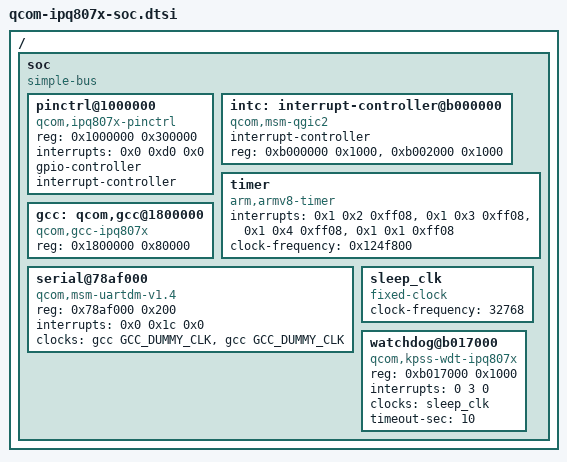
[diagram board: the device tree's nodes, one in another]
/*
 * Copyright (c) 2016, The Linux Foundation. All rights reserved.
 *
 * Permission to use, copy, modify, and/or distribute this software for any
 * purpose with or without fee is hereby granted, provided that the above
 * copyright notice and this permission notice appear in all copies.
 *
 * THE SOFTWARE IS PROVIDED "AS IS" AND THE AUTHOR DISCLAIMS ALL WARRANTIES
 * WITH REGARD TO THIS SOFTWARE INCLUDING ALL IMPLIED WARRANTIES OF
 * MERCHANTABILITY AND FITNESS. IN NO EVENT SHALL THE AUTHOR BE LIABLE FOR
 * ANY SPECIAL, DIRECT, INDIRECT, OR CONSEQUENTIAL DAMAGES OR ANY DAMAGES
 * WHATSOEVER RESULTING FROM LOSS OF USE, DATA OR PROFITS, WHETHER IN AN
 * ACTION OF CONTRACT, NEGLIGENCE OR OTHER TORTIOUS ACTION, ARISING OUT OF
 * OR IN CONNECTION WITH THE USE OR PERFORMANCE OF THIS SOFTWARE.
 */
#include <dt-bindings/reset/qcom,gcc-ipq807x.h>

/ {
	soc: soc {
		#address-cells = <0x1>;
		#size-cells = <0x1>;
		ranges = <0x0 0x0 0x0 0xffffffff>;
		compatible = "simple-bus";

		pinctrl@1000000 {
			compatible = "qcom,ipq807x-pinctrl";
			reg = <0x1000000 0x300000>;
			interrupts = <0x0 0xd0 0x0>;
			gpio-controller;
			#gpio-cells = <0x2>;
			interrupt-controller;
			#interrupt-cells = <0x2>;
		};

		intc: interrupt-controller@b000000 {
			compatible = "qcom,msm-qgic2";
			interrupt-controller;
			#interrupt-cells = <0x3>;
			reg = <0xb000000 0x1000>,
			<0xb002000 0x1000>;
		};

		timer {
			compatible = "arm,armv8-timer";
			interrupts = <0x1 0x2 0xff08>,
				     <0x1 0x3 0xff08>,
				     <0x1 0x4 0xff08>,
				     <0x1 0x1 0xff08>;
			clock-frequency = <0x124f800>;
		};


		gcc: qcom,gcc@1800000 {
			compatible = "qcom,gcc-ipq807x";
			reg = <0x1800000 0x80000>;
			#clock-cells = <0x1>;
		};

		serial@78af000 {
			compatible = "qcom,msm-uartdm-v1.4", "qcom,msm-uartdm";
			reg = <0x78af000 0x200>;
			interrupts = <0x0 0x1c 0x0>;
			status = "ok";
			clocks = <&gcc GCC_DUMMY_CLK>,
				 <&gcc GCC_DUMMY_CLK>;
			clock-names = "core", "iface";
		};

		sleep_clk: sleep_clk {
			compatible = "fixed-clock";
			clock-frequency = <32768>;
			#clock-cells = <0>;
		};

		watchdog@b017000 {
			compatible = "qcom,kpss-wdt-ipq807x";
			reg = <0xb017000 0x1000>;
			interrupt-names = "bark_irq";
			interrupts = <0 3 0>;
			clocks = <&sleep_clk>;
			timeout-sec = <10>;
		};

	};
};
